AUTOSAR XML (schema 4-2-2)
standard types defined: float32
package /DataTypes
  impl type float32_impl: category=VALUE, base-type=float32
package /PortInterfaces
  sender receiver interface IExample
    data value: type=float32_impl
package /ComponentTypes
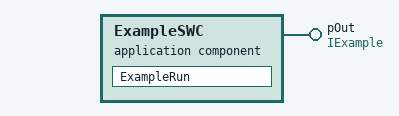
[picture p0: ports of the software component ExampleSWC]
  application sw component type ExampleSWC
    provide port pOut: provided-interface=IExample
    behavior ExampleSWC_InternalBehavior
      runnable ExampleRun
